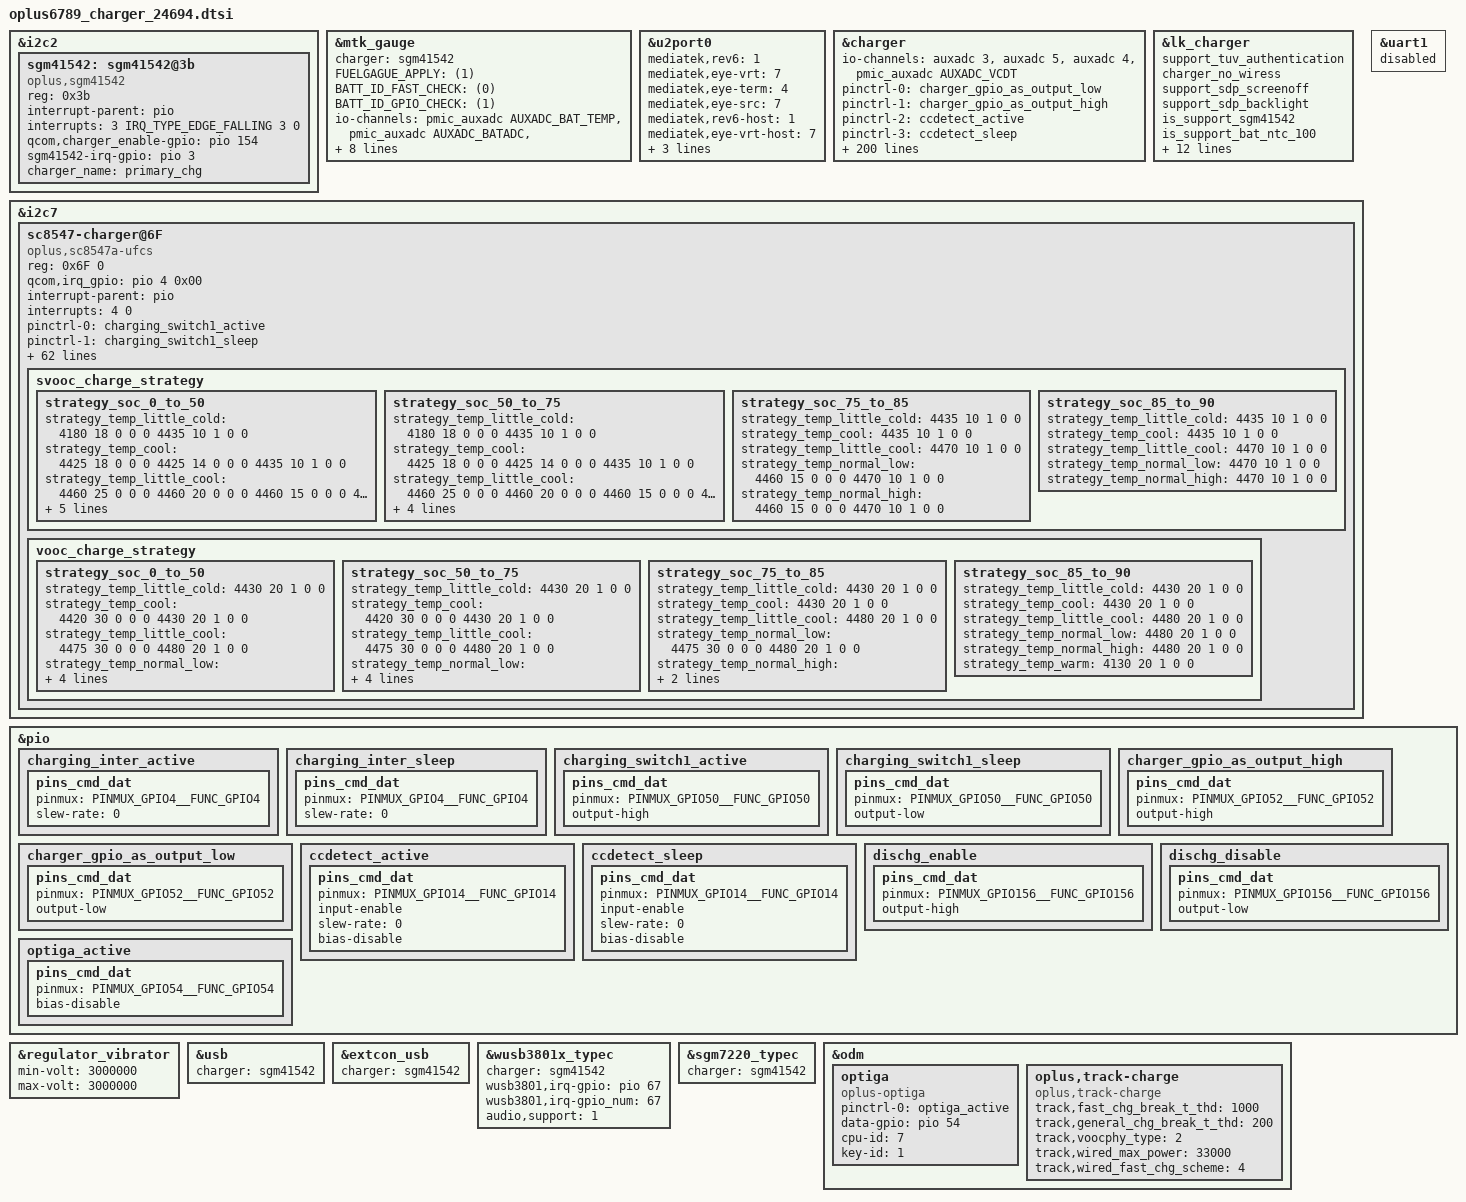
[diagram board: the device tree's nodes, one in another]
// SPDX-License-Identifier: GPL-2.0-only
/*
* Copyright (C) 2018-2020 Oplus. All rights reserved.
*/
/*
 *
 * CPU:MT6789 doki
 * IRQB
 * CHG_INT(cp irq)                --> GPIO12(CP1)/GPIO10(CP2)
 * CC_INTB(cc login irq)          --> GPIO3
 * EINT_CHG_M(main irq)           --> GPIO4
 *
 * GPIO
 * MAIN/CCLOGIN_SCL               --> GPIO48(SCL5)
 * MAIN/CCLOGIN_SDA               --> GPIO49(SDA5)
 * SW_CTRL(uart/vooc switch)      --> GPIO155(USB_SWITCH_2)
 * DISCHARGE_EN(防烧口)           -->
 * CHARGER_PUMP1_SCL               --> GPIO144(CP1_SCL7)
 * CHARGER_PUMP1_SDA               --> GPIO145(CP1_SDA7)
 * CHARGER_PUMP2_SCL               --> GPIO146(CP2_SCL8)
 * CHARGER_PUMP2_SDA               --> GPIO147(CP2_SDA8)
 * USB_ON(usb/uart&vooc switch)    --> GPIO151(USB_SWITCH_1)
 *
 * AUXADC:
 * 0				-->
 * 1				-->
 * 2				--> USB_TEM1_ADC
 * 3				--> USB_TEM2_ADC
 * 4				--> BAT_ID_ADC_OUT
 * 5				--> SUB_BAT_TEM
 * 6				-->
 * 7				-->
 * 8				-->
 */

#include <dt-bindings/iio/mt635x-auxadc.h>

&i2c2 {
	sgm41542:sgm41542@3b {
		status = "okay";
		compatible = "oplus,sgm41542";
		reg = <0x3b>;
		interrupt-parent = <&pio>;
		interrupts = <3 IRQ_TYPE_EDGE_FALLING 3 0>;
		qcom,charger_enable-gpio = <&pio 154 0x00>;
		sgm41542-irq-gpio = <&pio 3 0x00>;
		charger_name = "primary_chg";
	};
};

&mtk_gauge {
	status = "okay";
	charger = <&sgm41542>;
	FUELGAGUE_APPLY = <(1)>;
	BATT_ID_FAST_CHECK = <(0)>;
	BATT_ID_GPIO_CHECK = <(1)>;
	io-channels = <&pmic_auxadc AUXADC_BAT_TEMP>,
				<&pmic_auxadc AUXADC_BATADC>,
				<&pmic_auxadc AUXADC_VBIF>,
				<&pmic_auxadc AUXADC_IMP>,
				<&pmic_auxadc AUXADC_IMIX_R>,
				<&auxadc 4>;
	io-channel-names = "pmic_battery_temp",
					"pmic_battery_voltage",
					"pmic_bif_voltage",
					"pmic_ptim_voltage",
					"pmic_ptim_r",
					 "auxadc4-batt_id_v";
	batt_id_gpio = <&pio 105 0x00>;
	IS_BATTERY_GPIO_COMPATIBLE_SUPPROT = <(1)>;
	IS_BATTERY_NTC_100_SUPPROT = <(1)>;
	//IS_SUBBOARD_TEMP_SUPPORT = <(1)>;
	Enable_Is_Force_Full = <(1)>;
	CAR_TUNE_VALUE = <(100)>;
	#include "mediatek/bat_setting/mt6789_24694_battery_prop_dim2_ext.dtsi"
	#include "mediatek/bat_setting/mt6789_24694_battery_table_ext.dtsi"
};

&u2port0 {
	mediatek,rev6 = <1>;
	mediatek,eye-vrt = <7>;
	mediatek,eye-term = <4>;
	mediatek,eye-src = <7>;
	mediatek,rev6-host = <1>;
	mediatek,eye-vrt-host = <7>;
	mediatek,eye-term-host = <4>;
	mediatek,eye-src-host = <7>;
	mediatek,discth = <7>;
};

&charger {

	io-channels = <&auxadc 3>,<&auxadc 5>,<&auxadc 4>,<&pmic_auxadc AUXADC_VCDT>;
	io-channel-names = "auxadc3-charger_id","usb_temp_v_l","usb_temp_v_r","pmic_vbus_voltage";
	pinctrl-names = "charger_gpio_as_output_low","charger_gpio_as_output_high",
					"ccdetect_active","ccdetect_sleep","dischg_enable","dischg_disable";
	pinctrl-0 = <&charger_gpio_as_output_low>;
	pinctrl-1 = <&charger_gpio_as_output_high>;
	pinctrl-2 = <&ccdetect_active>;
	pinctrl-3 = <&ccdetect_sleep>;
	pinctrl-4 = <&dischg_enable>;
	pinctrl-5 = <&dischg_disable>;

	gauge = <&mtk_gauge>;
	charger = <&sgm41542>;

	//for oplus chg framework:
	qcom,pd_input_current_charger_ma = <2000>;
	qcom,qc_input_current_charger_ma = <2000>;
	qcom,input_current_charger_ma = <3000>;
	qcom,input_current_usb_ma = <500>;
	qcom,input_current_cdp_ma = <1500>;
	qcom,input_current_camera_ma = <1200>;
	qcom,input_current_calling_ma = <1500>;

	qcom,led_warm_bat_decidegc = <350>;
	qcom,led_high_bat_decidegc = <370>;
	qcom,input_current_led_ma = <1200>;
	qcom,input_current_led_ma_high = <1200>;
	qcom,input_current_led_ma_warm = <1500>;
	qcom,input_current_led_ma_normal = <3000>;
	qcom,input_current_led_ma_forcmcc = <500>;
	qcom,input_current_led_ma_limit_high = <1200>;

	qcom,vooc_temp_bat_normal_decidegc = <350>;
	qcom,vooc_temp_bat_warm_decidegc = <370>;
	qcom,vooc_temp_bat_hot_decidegc = <440>;
	qcom,input_current_vooc_led_ma_high = <1200>;
	qcom,input_current_vooc_led_ma_warm = <1800>;
	qcom,input_current_vooc_led_ma_normal = <3600>;
	qcom,input_current_vooc_ma_normal = <3600>;
	qcom,input_current_vooc_ma_warm = <3200>;
	qcom,input_current_vooc_ma_high = <2200>;

	qcom,overtemp_bat_decidegc = <350>;
	qcom,iterm_disabled = <0>;
	//sw_full_count = <25>;
	qcom,iterm_ma = <420>;
	qcom,recharge-mv = <100>;

	qcom,batt_capacity_mah = <8360>; /*typical capacity*/
	//qcom,batt_capacity_mah = <4880>; /*rated capacity*/
	qcom,usb_high_than_bat_decidegc = <168>;

	qcom,removed_bat_decidegc = <390>;  /* < -39C */

	qcom,cold_bat_decidegc = <100>;  /* -10C ~ 0C */
	qcom,temp_cold_vfloat_mv = <4435>;
	qcom,temp_freeze_fastchg_current_ma_high = <1600>;
	qcom,temp_freeze_fastchg_current_ma_low = <1200>;
	qcom,temp_freeze_fastchg_current_ma = <900>;
	qcom,temp_cold_fastchg_current_ma = <1200>;
	qcom,temp_cold_fastchg_current_ma_high = <1600>;

	qcom,little_cold_bat_decidegc = <0>;    /* 0C ~ 5C */
	qcom,temp_little_cold_vfloat_mv = <4435>;
	qcom,temp_little_cold_fastchg_current_ma_high = <3000>;
	qcom,temp_little_cold_fastchg_current_ma_low = <2500>;
	qcom,temp_little_cold_fastchg_current_ma = <3000>;
	qcom,qc_temp_little_cold_fastchg_current_ma_high = <2594>;
	qcom,qc_temp_little_cold_fastchg_current_ma_low = <3300>;
	qcom,pd_temp_little_cold_fastchg_current_ma_high = <2594>;
	qcom,pd_temp_little_cold_fastchg_current_ma_low = <3300>;

	qcom,cool_bat_decidegc = <50>;  /* 5C ~ 12C */
	qcom,temp_cool_vfloat_mv = <4435>;
	qcom,temp_cool_fastchg_current_ma_high = <3000>;
	qcom,temp_cool_fastchg_current_ma_low = <3000>;
	qcom,qc_temp_cool_fastchg_current_ma_high = <3300>;
	qcom,qc_temp_cool_fastchg_current_ma_low = <3300>;
	qcom,pd_temp_cool_fastchg_current_ma_high = <3300>;
	qcom,pd_temp_cool_fastchg_current_ma_low = <3300>;

	qcom,little_cool_bat_decidegc = <120>;  /* 12C ~ 16C */
	qcom,temp_little_cool_vfloat_mv = <4435>;
	qcom,temp_little_cool_fastchg_current_ma = <2200>;
	qcom,pd_temp_little_cool_fastchg_current_ma = <3300>;
	qcom,qc_temp_little_cool_fastchg_current_ma = <3300>;

	qcom,normal_bat_decidegc = <160>;       /* 16C ~ 45C */
	qcom,temp_normal_vfloat_mv = <4435>;
	qcom,temp_normal_fastchg_current_ma = <2200>;
	qcom,pd_temp_normal_fastchg_current_ma = <3300>;
	qcom,qc_temp_normal_fastchg_current_ma = <3300>;

	qcom,warm_bat_decidegc = <450>;         /* 45C ~ 53C */ /*8pin Bat Vooc project need add 3 degree C*/
	qcom,temp_warm_vfloat_mv = <4130>;
	qcom,temp_warm_fastchg_current_ma = <3000>;
	qcom,pd_temp_warm_fastchg_current_ma = <1300>;
	qcom,qc_temp_warm_fastchg_current_ma = <1300>;
	qcom,temp_warm_fastchg_current_ma_led_on = <1000>;

	qcom,hot_bat_decidegc = <530>;  /* > 53C */

	qcom,non_standard_vfloat_mv = <3980>;
	qcom,non_standard_fastchg_current_ma = <512>;

	qcom,short_c_bat_cv_mv = <4330>;
	qcom,short_c_bat_vfloat_mv = <3800>;
	qcom,short_c_bat_fastchg_current_ma = <512>;
	qcom,short_c_bat_vfloat_sw_limit = <3750>;

	qcom,cold_vfloat_sw_limit = <4385>;
	qcom,little_cold_vfloat_sw_limit = <4385>;
	qcom,cool_vfloat_sw_limit = <4385>;
	qcom,little_cool_vfloat_sw_limit = <4385>;
	qcom,normal_vfloat_sw_limit = <4385>;
	qcom,warm_vfloat_sw_limit = <4080>;
	qcom,non_standard_vfloat_sw_limit = <3930>;

	qcom,max_chg_time_sec = <72000>;
	qcom,charger_hv_thr = <5800>;
	qcom,charger_recv_thr = <5500>;
	qcom,charger_lv_thr = <3400>;
	qcom,vbatt_full_thr = <4400>;
	qcom,vbatt_hv_thr = <4600>;

	qcom,vfloat_step_mv = <16>;
	qcom,non_standard_vfloat_over_sw_limit = <3990>;
	qcom,cold_vfloat_over_sw_limit = <4445>;
	qcom,little_cold_vfloat_over_sw_limit = <4445>;
	qcom,cool_vfloat_over_sw_limit = <4445>;
	qcom,little_cool_vfloat_over_sw_limit = <4445>;
	qcom,normal_vfloat_over_sw_limit = <4440>;
	qcom,warm_vfloat_over_sw_limit = <4140>;

	qcom,vbatt_power_off = <3300>;
	qcom,vbatt_soc_1 = <3410>;
	qcom,vooc_project = <0>;
	qcom,vbatt_num = <1>;
	qcom,new_ui_warning_support;
	qcom,smart_charging_screenoff;
	qcom,smart_charge_version = <1>;

	qcom,support_usbtemp_protect_v2;
	qcom,usbtemp_batt_temp_low = <50>;
	qcom,usbtemp_batt_temp_high = <50>;
	qcom,usbtemp_ntc_temp_low = <57>;
	qcom,usbtemp_ntc_temp_high = <69>;
	qcom,usbtemp_temp_gap_low_with_batt_temp = <7>;
	qcom,usbtemp_temp_gap_high_with_batt_temp = <12>;
	qcom,usbtemp_temp_gap_low_without_batt_temp = <12>;
	qcom,usbtemp_temp_gap_high_without_batt_temp = <24>;
	qcom.usbtemp_rise_fast_temp_low = <3>;
	qcom.usbtemp_rise_fast_temp_high = <3>;
	qcom.usbtemp_rise_fast_temp_count_low = <30>;
	qcom.usbtemp_rise_fast_temp_count_high = <20>;

	qcom,usbtemp_cool_down_ntc_low = <54>;
	qcom,usbtemp_cool_down_ntc_high = <65>;
	qcom,usbtemp_cool_down_gap_low = <12>;
	qcom,usbtemp_cool_down_gap_high = <20>;
	qcom,usbtemp_cool_down_recover_ntc_low = <48>;
	qcom,usbtemp_cool_down_recover_ntc_high = <60>;
	qcom,usbtemp_cool_down_recover_gap_low = <6>;
	qcom,usbtemp_cool_down_recover_gap_high = <15>;

	qcom,normal_vterm_hw_inc = <18>;
	qcom,non_normal_vterm_hw_inc = <18>;
	qcom,usbtemp_batttemp_gap = <12>;

	qcom,ff1_normal_fastchg_ma = <1500>; /*12C~35c*/
	qcom,ff1_warm_fastchg_ma = <1700>;	/* 35C ~ 40c */
	qcom,ff1_exit_step_ma = <400>;
	qcom,ff1_warm_exit_step_ma = <200>;

	qcom,ffc2_normal_fastchg_ma = <1300>;/*12C~35c*/
	qcom,ffc2_warm_fastchg_ma = <1700>;	/* 35C ~ 40c */
	qcom,ffc2_temp_warm_decidegc = <350>;
	qcom,ffc2_temp_high_decidegc = <400>;
	qcom,ffc2_temp_low_decidegc = <120>;
	qcom,ffc2_exit_step_ma = <200>;
	qcom,ffc2_warm_exit_step_ma = <200>;

	qcom,ffc_normal_vfloat_sw_limit = <4475>;
	qcom,ffc_temp_normal_vfloat_mv = <4550>;
	qcom,ffc_normal_vfloat_over_sw_limit = <4550>;
	qcom,ffc_warm_vfloat_sw_limit = <4475>;

	qcom,ffc2_normal_vfloat_sw_limit = <4475>;
	qcom,ffc2_temp_normal_vfloat_mv = <4550>;
	qcom,ffc2_normal_vfloat_over_sw_limit = <4550>;
	qcom,ffc2_warm_vfloat_sw_limit = <4475>;


	qcom,default_iterm_ma = <420>;
	qcom,default_temp_normal_fastchg_current_ma = <3000>;
	qcom,default_normal_vfloat_sw_limit = <4385>;
	qcom,default_temp_normal_vfloat_mv = <4435>;
	qcom,default_normal_vfloat_over_sw_limit = <4445>;

	qcom,default_temp_little_cool_fastchg_current_ma = <3000>;
	qcom,default_little_cool_vfloat_sw_limit = <4385>;
	qcom,default_temp_little_cool_vfloat_mv = <4435>;
	qcom,default_little_cool_vfloat_over_sw_limit = <4445>;

	//for PD9V or QC9V
	qcom,vbatt_pdqc_to_5v_thr = <4500>;
	qcom,vbatt_pdqc_to_9v_thr = <4500>;

	//for control:
	//qcom,suspend_after_full;
	qcom,check_batt_full_by_sw;
	qcom,chg_ctrl_by_lcd;
	qcom,chg_ctrl_by_camera;
	qcom,chg_ctrl_by_calling;
	qcom,sw_vfloat_over_protect_enable;
	qcom,usbtemp_dischg_by_platpmic;
	qcom,ffc_support;
	qcom,chargerid_vol_disable;
	qcom,support_ntc_01c_precision;
	qcom,voocphy_support = <2>;
	//qcom,external_authenticate;
	qcom,chargerid_support;
	qcom,vooc_show_ui_soc_decimal;
	qcom,ui_soc_decimal_speedmin = <20>;//2A
	qcom,ccdetect_by_wd0;
	qcom,hvdcp_disabled; //turn off hvdcp func for doki
	qcom,sgm41542_support;
	//GPIO config:
	qcom,chargerid_switch-gpio = <&pio 52 0x00>;
	qcom,dischg-gpio = <&pio 156 0x00>;
	qcom,ccdetect-gpio = <&pio 14 0x00>;

	qcom,vooc-max-input-volt-support = <10000>;     //10V
	qcom,vooc-max-input-current-support = <3000>;   //3A
};

&lk_charger {
	support_tuv_authentication;
	charger_no_wiress;
	//sub_board_temp_support;
	support_sdp_screenoff;
	support_sdp_backlight;
        is_support_sgm41542;
        is_support_bat_ntc_100;
	is_support_bat_gpio_compatible;
	max_charger_voltage = <15000000>;
	boot_battery_voltage = <3400000>;
	usb_charger_current = <500000>;
	ac_charger_current = <2050000>;
	ac_charger_input_current = <1500000>;
	non_std_ac_charger_current = <750000>;
	charging_host_charger_current = <1500000>;
	ta_ac_charger_current = <1500000>;
	pd_charger_current = <500000>;
	bat_id_gpio = <105>;
	switch_ic_enable_gpio = <154>;
};

&i2c7 {
	status = "okay";
	sc8547-charger@6F{
		status = "okay";
		compatible = "oplus,sc8547a-ufcs";
		reg = <0x6F 0>;

		qcom,irq_gpio = <&pio 4 0x00>;
		interrupt-parent = <&pio>;
		interrupts = <4 0>;

		pinctrl-names = "switch1_act_switch2_act", "switch1_sleep_switch2_sleep",
					"charging_inter_active", "charging_inter_sleep";
		pinctrl-0 = <&charging_switch1_active>;
		pinctrl-1 = <&charging_switch1_sleep>;
		pinctrl-2 = <&charging_inter_active>;
		pinctrl-3 = <&charging_inter_sleep>;

		qcom,charging_switch1-gpio = <&pio 50 0x00>;

		ocp_reg = <0xa>;

		/*qcom,voocphy_dual_cp_support;*/
		qcom,slave_cp_enable_thr = <1900>;		//2000-100mA
		qcom,slave_cp_disable_thr_high = <1600>;	//1500+100mA
		qcom,voocphy_current_default = <60>;

		qcom,svooc_cool_down_current_limit = <60 20 20 24 30 34 40 44 50 54 60 60 60 60 60>;
		qcom,vooc_cool_down_current_limit = <30 20 20 20 30 30 30 30 30 30 30 30 30 30 30>;

		qcom,vooc_multistep_initial_batt_temp = <1000>;

		qcom,vooc_strategy_normal_current = <100>;
		qcom,vooc_normal_to_little_cool_current = <100>;
		qcom,vooc_batt_over_high_temp = <500>;

		qcom,vooc-low-temp = <0>;
		qcom,vooc-high-temp = <500>;
		qcom,vooc-low-soc = <0>;
		qcom,vooc-high-soc = <90>;
		qcom,vooc-warm-allow-vol = <4000>;
		qcom,vooc-warm-allow-soc = <50>;

		qcom,vooc_little_cold_temp = <50>;
		qcom,vooc_cool_temp = <120>;
		qcom,vooc_little_cool_temp = <160>;
		qcom,vooc_normal_low_temp = <250>;
		qcom,vooc-normal-high-temp = <440>;

		qcom,vooc_strategy1_batt_high_temp0 = <385>;
		qcom,vooc_strategy1_batt_high_temp1 = <395>;
		qcom,vooc_strategy1_batt_high_temp2 = <420>;
		qcom,vooc_strategy1_batt_low_temp2 = <410>;
		qcom,vooc_strategy1_batt_low_temp1 = <385>;
		qcom,vooc_strategy1_batt_low_temp0 = <375>;

		qcom,vooc_strategy1_high_current0 = <60>;
		qcom,vooc_strategy1_high_current1 = <60>;
		qcom,vooc_strategy1_high_current2 = <40>;
		qcom,vooc_strategy1_low_current2 = <40>;
		qcom,vooc_strategy1_low_current1 = <60>;
		qcom,vooc_strategy1_low_current0 = <60>;

		qcom,voocphy_freq_mincore = <1800000>;
		qcom,voocphy_freq_midcore = <1800000>;
		qcom,voocphy_freq_maxcore = <1800000>;
		qcom,voocphy_current_change_timeout = <100>;

		qcom,voocphy_ibat_over_current = <7500>;
		qcom,voocphy_svooc_cp_max_ibus = <3500>;
		qcom,voocphy_vooc_cp_max_ibus = <3500>;
		qcom,voocphy_cp_max_ibus = <3500>;

		qcom,vooc_little_cold_full_voltage = <4434>;
		qcom,vooc_cool_full_voltage = <4434>;
		qcom,vooc_warm_full_voltage = <4130>;
		qcom,vooc_1time_full_voltage = <4480>;
		qcom,vooc_ntime_full_voltage = <4470>;
		qcom,low_curr_full_t1 = <120>;
		qcom,low_curr_full_t2 = <350>;
		qcom,low_curr_full_t3 = <430>;
		qcom,range1_low_curr_full = <1150 4470
						1050 4465
						950 4450
						850 4450
						750 4450>;
		qcom,range2_low_curr_full = <1550 4470
						1450 4465
						1350 4450
						1250 4450
						1150 4450>;

		svooc_batt_sys_curve = <0 1 0 1 0 0 0	// 4000mA
					1 1 1 1 0 0 0	// 4604mV
					0 0 1 1 0 1 0	// 2600mA
					1 1 1 1 0 0 0	// 4604mV
					0 0 0 1 0 1 1	// 1100mA
					1 1 1 1 0 0 0>;	// 4604mV

		vooc_batt_sys_curve =  <0 1 0 1 0 0 0	// 4000mA
					1 1 1 1 0 0 0	// 4604mV
					0 0 1 1 0 1 0	// 2600mA
					1 1 1 1 0 0 0	// 4604mV
					0 0 0 1 0 1 1	// 1100mA
					1 1 1 1 0 0 0>;	// 4604mV

		svooc_charge_strategy {
			strategy_soc_0_to_50 {
				strategy_temp_little_cold =	<4180 18 0 0 0
								 4435 10 1 0 0>;
				strategy_temp_cool =   <4425 18 0 0 0
								 4425 14 0 0 0
								 4435 10 1 0 0>;
				strategy_temp_little_cool = <4460 25 0 0 0
								 4460 20 0 0 0
								 4460 15 0 0 0
								 4470 10 1 0 0>;
				strategy_temp_normal_low =	<4460 30 0 1200 0	//min*60*1000/500
								 4460 25 0 1200 0
								 4460 23 0 0 0
								 4460 20 0 0 0
								 4460 15 0 0 0
								 4470 10 1 0 0>;
				strategy_temp_normal_high =	<4460 30 0 1200 0
								 4460 25 0 1200 0
								 4460 23 0 0 0
								 4460 20 0 0 0
								 4460 15 0 0 0
								 4470 10 1 0 0>;
				strategy_temp_warm = <4130 20 1 0 0>;
			};

			strategy_soc_50_to_75 {
				strategy_temp_little_cold =	<4180 18 0 0 0
								 4435 10 1 0 0>;
				strategy_temp_cool =		<4425 18 0 0 0
								 4425 14 0 0 0
								 4435 10 1 0 0>;
				strategy_temp_little_cool =	<4460 25 0 0 0
								 4460 20 0 0 0
								 4460 15 0 0 0
								 4470 10 1 0 0>;
				strategy_temp_normal_low =	<4460 25 0 1200 0
								 4460 23 0 0 0
								 4460 20 0 0 0
								 4460 15 0 0 0
								 4470 10 1 0 0>;
				strategy_temp_normal_high =	<4460 25 0 1200 0
								 4460 23 0 0 0
								 4460 20 0 0 0
								 4460 15 0 0 0
								 4470 10 1 0 0>;
			};

			strategy_soc_75_to_85 {
				strategy_temp_little_cold = <4435 10 1 0 0>;
				strategy_temp_cool =		<4435 10 1 0 0>;
				strategy_temp_little_cool =	<4470 10 1 0 0>;
				strategy_temp_normal_low =	<4460 15 0 0 0
								4470 10 1 0 0>;
				strategy_temp_normal_high =	<4460 15 0 0 0
								4470 10 1 0 0>;
			};

			strategy_soc_85_to_90 {
				strategy_temp_little_cold = <4435 10 1 0 0>;
				strategy_temp_cool =		<4435 10 1 0 0>;
				strategy_temp_little_cool =	<4470 10 1 0 0>;
				strategy_temp_normal_low =	<4470 10 1 0 0>;
				strategy_temp_normal_high =	<4470 10 1 0 0>;
			};
		};

		vooc_charge_strategy {
			strategy_soc_0_to_50 {
				strategy_temp_little_cold =	<4430 20 1 0 0>; /*0-5C*/
				strategy_temp_cool =	<4420 30 0 0 0
								 4430 20 1 0 0>;			/*5-12C*/
				strategy_temp_little_cool =	<4475 30 0 0 0
								 4480 20 1 0 0>;			/*12-16C*/
				strategy_temp_normal_low =	<4475 30 0 0 0
								 4480 20 1 0 0>;			/*16-25C*/
				strategy_temp_normal_high =	<4475 30 0 0 0
								 4480 20 1 0 0>;			/*25C-44C*/
				strategy_temp_warm = <4130 20 1 0 0>;
			};

			strategy_soc_50_to_75 {
				strategy_temp_little_cold =	<4430 20 1 0 0>;
				strategy_temp_cool =	<4420 30 0 0 0
								 4430 20 1 0 0>;
				strategy_temp_little_cool =	<4475 30 0 0 0
								 4480 20 1 0 0>;
				strategy_temp_normal_low =	<4475 30 0 0 0
								 4480 20 1 0 0>;
				strategy_temp_normal_high =	<4475 30 0 0 0
								 4480 20 1 0 0>;
				strategy_temp_warm = <4130 20 1 0 0>;
			};

			strategy_soc_75_to_85 {
				strategy_temp_little_cold =	<4430 20 1 0 0>;
				strategy_temp_cool =	<4430 20 1 0 0>;
				strategy_temp_little_cool =	<4480 20 1 0 0>;
				strategy_temp_normal_low =	<4475 30 0 0 0
								 4480 20 1 0 0>;
				strategy_temp_normal_high =	<4475 30 0 0 0
								 4480 20 1 0 0>;
				strategy_temp_warm = <4130 20 1 0 0>;
			};

			strategy_soc_85_to_90 {
				strategy_temp_little_cold =	<4430 20 1 0 0>;
				strategy_temp_cool =	<4430 20 1 0 0>;
				strategy_temp_little_cool =	<4480 20 1 0 0>;
				strategy_temp_normal_low =	<4480 20 1 0 0>;
				strategy_temp_normal_high =	<4480 20 1 0 0>;
				strategy_temp_warm = <4130 20 1 0 0>;
			};
		};

	};
};

&uart1 {
	status = "disabled";
};

&pio {
	charging_inter_active: charging_inter_active {
		pins_cmd_dat {
			pinmux = <PINMUX_GPIO4__FUNC_GPIO4>;
			slew-rate = <0>;
		};
	};

	charging_inter_sleep: charging_inter_sleep {
		pins_cmd_dat {
			pinmux = <PINMUX_GPIO4__FUNC_GPIO4>;
			slew-rate = <0>;
		};
	};

	charging_switch1_active: charging_switch1_active {
		pins_cmd_dat {
			pinmux = <PINMUX_GPIO50__FUNC_GPIO50>;
			output-high;
		};
	};

	charging_switch1_sleep: charging_switch1_sleep {
		pins_cmd_dat {
			pinmux = <PINMUX_GPIO50__FUNC_GPIO50>;
			output-low;
		};
	};

	charger_gpio_as_output_high: charger_gpio_as_output_high {
		pins_cmd_dat {
			pinmux = <PINMUX_GPIO52__FUNC_GPIO52>;
			output-high;
		};
	};
	charger_gpio_as_output_low: charger_gpio_as_output_low {
		pins_cmd_dat {
			pinmux = <PINMUX_GPIO52__FUNC_GPIO52>;
			output-low;
		};
	};
	ccdetect_active: ccdetect_active {
		pins_cmd_dat {
			pinmux = <PINMUX_GPIO14__FUNC_GPIO14>;
			input-enable;
			slew-rate = <0>;
			bias-disable;
		};
	};
	ccdetect_sleep: ccdetect_sleep {
		pins_cmd_dat {
			pinmux = <PINMUX_GPIO14__FUNC_GPIO14>;
			input-enable;
			slew-rate = <0>;
			bias-disable;
		};
	};
	dischg_enable: dischg_enable {
		pins_cmd_dat {
			pinmux = <PINMUX_GPIO156__FUNC_GPIO156>;
			output-high;
		};
	};
	dischg_disable: dischg_disable {
		pins_cmd_dat {
			pinmux = <PINMUX_GPIO156__FUNC_GPIO156>;
			output-low;
		};
	};
};

&regulator_vibrator{
	min-volt = <3000000>;
	max-volt = <3000000>;
};

&usb {
	charger = <&sgm41542>;
	status = "okay";
};

&extcon_usb {
	charger = <&sgm41542>;
	status = "okay";
};

&charger {
	charger = <&sgm41542>;
	status = "okay";
};

&wusb3801x_typec {
	charger = <&sgm41542>;
	wusb3801,irq-gpio = <&pio 67 0x0>;
	wusb3801,irq-gpio_num = <67>;
	audio,support = <1>;
	status = "okay";
};

&sgm7220_typec {
	charger = <&sgm41542>;
	status = "okay";
};

&odm {
	optiga {
		compatible = "oplus-optiga";
		status = "ok";
		pinctrl-names = "optiga_active";
		pinctrl-0 = <&optiga_active>;
		data-gpio = <&pio 54 0x00>;
		cpu-id = <7>;
		key-id = <1>;
	};

	oplus,track-charge {
		compatible = "oplus,track-charge";
		track,fast_chg_break_t_thd = <1000>;
		track,general_chg_break_t_thd = <200>;
		track,voocphy_type = <2>;
		track,wired_max_power = <33000>;
		track,wired_fast_chg_scheme = <4>;
	};
};


&pio {
	optiga_active: optiga_active {
		pins_cmd_dat {
			pinmux = <PINMUX_GPIO54__FUNC_GPIO54>;
			//slew-rate = <1>;
			bias-disable;
		};
	};
};
#include "oplus6789_charger_24694_battery_2.dtsi"
